# STM32U385 register map
File version: 1.0
CPU: CM33 r0p1, little endian, MPU, FPU, 4 interrupt priority bits
Registers are 32-bit, read-write, reset 0x0 unless marked. A register's access mark holds for its fields unless they carry their own. Offsets are from the block's base; [hi:lo] are bit positions; {n}, {i} and the like mark numbered series; 'fields as' and 'values as' point back to an identical list.

## RAMCFG — RAMCFG address block description
Base 0x40026000
Same registers: SEC_RAMCFG 0x50026000
0x00 RAMCFG_M1CR — RAMCFG memory 1 control register
  [8] SRAMER — SRAM erase
    0=No erase operation ongoing; 1=Erase operation ongoing
0x08 RAMCFG_M1ISR ro — RAMCFG memory 1 interrupt status register
  [8] SRAMBUSY — SRAM busy with erase operation
    0=No erase operation ongoing; 1=Erase operation ongoing
0x28 RAMCFG_M1ERKEYR wo — RAMCFG memory 1 erase key register
  [7:0] ERASEKEY — Erase write protection key
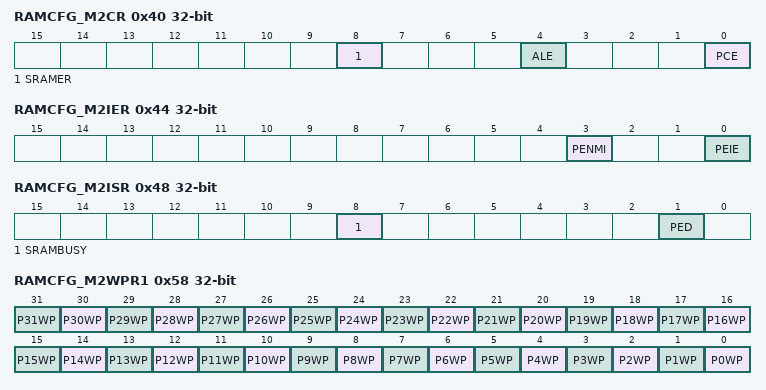
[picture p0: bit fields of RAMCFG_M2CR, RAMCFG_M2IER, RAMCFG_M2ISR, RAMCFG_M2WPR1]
0x40 RAMCFG_M2CR (reset mask 0xFFFFFFF0) — RAMCFG memory 2 control register
  [8] SRAMER — SRAM erase
    0=No erase operation ongoing; 1=Erase operation ongoing
  [4] ALE — Address latch enable in case of parity error
    0=Failing address not stored in the SRAM2 parity error address registers; 1=Failing address stored in the SRAM2 parity error address registers
  [0] PCE — Parity check enable
    0=Parity check disabled; 1=Parity check enabled
0x44 RAMCFG_M2IER — RAMCFG memory 2 interrupt enable register
  [3] PENMI — Parity error NMI
    0=NMI not generated in case of Parity error; 1=NMI generated in case of Parity error
  [0] PEIE — Parity error interrupt enable
    0=Parity error interrupt disabled; 1=Parity error interrupt enabled
0x48 RAMCFG_M2ISR ro — RAMCFG memory 2 interrupt status register
  [8] SRAMBUSY — SRAM busy with erase operation
    0=No erase operation ongoing; 1=Erase operation ongoing
  [1] PED — Parity error detected
    0=No Parity error detected; 1=Parity error detected
0x50 RAMCFG_M2PEAR ro — RAMCFG memory 2 parity error address register
  [31:0] PEA — Parity error address
0x54 RAMCFG_M2ICR — RAMCFG memory 2 interrupt clear register
  [1] CPED — Clear parity error detected
0x58 RAMCFG_M2WPR1 — RAMCFG memory 2 write protection register 1
  [all] fields
    0=Write protection of SRAM2 1-Kbyte page y is disabled; 1=Write protection of SRAM2 1-Kbyte page y is enabled
  [n] P{n}WP (n=0..31) — SRAM2 1-Kbyte page y write protection
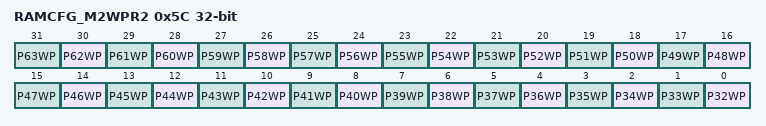
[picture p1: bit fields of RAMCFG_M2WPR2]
0x5C RAMCFG_M2WPR2 — RAMCFG memory 2 write protection register 2
  [all] fields
    values as the fields of RAMCFG_M2WPR1
  [n-32] P{n}WP (n=32..63) — SRAM2 1-Kbyte page y write protection
0x64 RAMCFG_M2PARKEYR wo — RAMCFG memory 2 parity key register
  [7:0] PARKEY — Parity write protection key
0x68 RAMCFG_M2ERKEYR wo — RAMCFG memory 2 erase key register
  [7:0] ERASEKEY — Erase write protection key

## RNG — RNG address block description
Base 0x420C0800
Same registers: SEC_RNG 0x520C0800
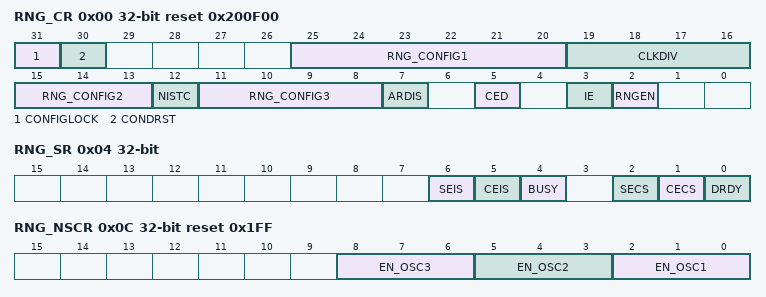
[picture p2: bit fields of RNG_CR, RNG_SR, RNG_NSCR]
0x00 RNG_CR reset 0x200F00 — RNG control register
  [31] CONFIGLOCK — RNG Config lock
    0=Writes to the RNG_NSCR, RNG_HTCR and the RNG_CR configuration bits [29:4] are allowed; 1=Writes to the RNG_NSCR, RNG_HTCR and the RNG_CR configuration bits [29:4] are ignored until the next RNG reset
  [30] CONDRST — Conditioning soft reset
  [25:20] RNG_CONFIG1 — RNG configuration 1
  [19:16] CLKDIV — Clock divider factor
    0=internal RNG clock after divider is similar to incoming RNG clock; 1=two RNG clock cycles per internal RNG clock; 2=2less thansup>2less than/sup> (= 4) RNG clock cycles per internal RNG clock; 15=2less thansup>15less than/sup> RNG clock cycles per internal clock (for example
  [15:13] RNG_CONFIG2 — RNG configuration 2
  [12] NISTC — NIST custom
    0=Hardware default values for NIST compliant RNG; 1=Custom values for NIST compliant RNG
  [11:8] RNG_CONFIG3 — RNG configuration 3
  [7] ARDIS — Auto reset disable
    0=Auto-reset is enabled; 1=Auto-reset is disabled
  [5] CED — Clock error detection
    0=Clock error detection is enabled; 1=Clock error detection is disabled
  [3] IE — Interrupt enable
    0=RNG interrupt is disabled; 1=RNG interrupt is enabled
  [2] RNGEN — True random number generator enable
    0=True random number generator disabled; 1=True random number generator enabled
0x04 RNG_SR — RNG status register
  [6] SEIS — Seed error interrupt status
    0=No faulty sequence detected; 1=At least one faulty sequence is detected
  [5] CEIS — Clock error interrupt status
    0=The RNG clock is correct (fless thansub>RNGCLKless than/sub>> fless thansub>HCLKless than/sub>/32); 1=The RNG clock before the internal divider is detected too slow (fless thansub>RNGCLKless than/sub>less than fless thansub>HCLKless than/sub>/32)
  [4] BUSY ro
    0=Idle; 1=Busy
  [2] SECS ro — Seed error current status
    0=No faulty sequence has currently been detected; 1=At least one of the following faulty sequence has been detected:
  [1] CECS ro — Clock error current status
    0=The RNG clock is correct (fless thansub>RNGCLKless than/sub>> fless thansub>HCLKless than/sub>/32); 1=The RNG clock is too slow (fless thansub>RNGCLKless than/sub>less than fless thansub>HCLKless than/sub>/32)
  [0] DRDY ro — Data ready
    0=No valid random data ready; 1=Valid random data ready
0x08 RNG_DR ro — RNG data register
  [31:0] RNDATA — Random data
0x0C RNG_NSCR reset 0x1FF — RNG noise source control register
  [8:6] EN_OSC3 — Each bit drives one oscillator enable signal input of instance number 3, gated with the RNGEN bit in RNG_CR (set bit to enable the oscillator).
  [5:3] EN_OSC2 — Each bit drives one oscillator enable signal input of instance number 2, gated with the RNGEN bit in RNG_CR (set bit to enable the oscillator).
  [2:0] EN_OSC1 — Each bit drives one oscillator enable signal input of instance number 1, gated with the RNGEN bit in RNG_CR (set bit to enable the oscillator).
0x10 RNG_HTCR0 reset 0x72AC — RNG health test control register 0
  [31:0] HTCFG — health test configuration
{0x10+4i} RNG_HTCR{i} reset 0xFFFF (i=1..3) — RNG health test control register {i}
  [31:0] HTCFG — health test configuration
